# APM32F445 register map
File version: 1.0
CPU: CM4 r0p1, little endian, MPU, FPU, 4 interrupt priority bits
Registers are 32-bit, read-write, reset 0x0 unless marked. A register's access mark holds for its fields unless they carry their own. Offsets are from the block's base; [hi:lo] are bit positions; {n}, {i} and the like mark numbered series.

## PDU0 — Programmable Delay Unit 0
Base 0x40036000
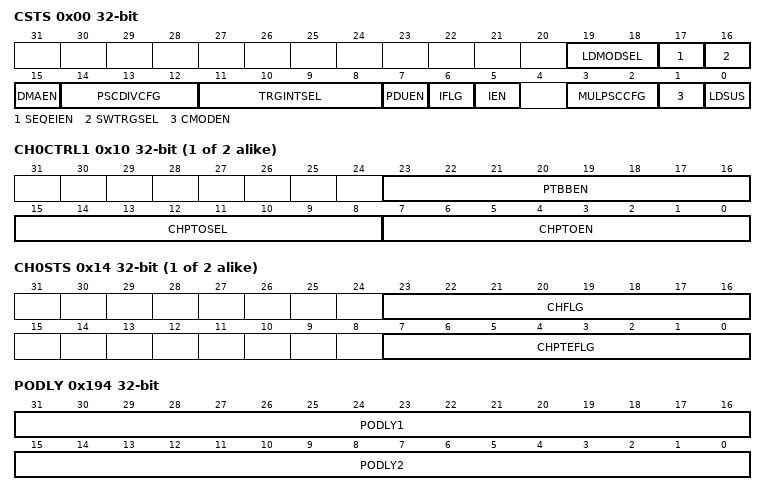
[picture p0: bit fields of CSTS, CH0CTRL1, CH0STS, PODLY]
0x00 CSTS — Control and Status register
  [19:18] LDMODSEL — Load Mode Select
    0=The internal registers are loaded with the values from their buffers, immediately after 1 is written to LDOK; 1=The internal registers are loaded with the values from their buffers when the PDU counter (CNT) = MOD + 1 CNT delay elapsed, after 1 is written to LDOK; 2=The internal registers are loaded with the values from their buffers when a trigger input event is detected, after 1 is written to LDOK; 3=The internal registers are loaded with the values from their buffers when either the PDU counter (CNT) = MOD + 1 CNT delay elapsed, or a trigger input event is detected, after 1 is written to LDOK
  [17] SEQEIEN — Sequence Error Interrupt Enable
    0=PDU sequence error interrupt disabled; 1=PDU sequence error interrupt enabled
  [16] SWTRGSEL wo — Software Trigger Select
  [15] DMAEN — DMA Enable
    0=DMA disabled; 1=DMA enabled
  [14:12] PSCDIVCFG — Prescaler Divider Configure
    0=Counting uses the peripheral clock divided by MULT (the multiplication factor); 1=Counting uses the peripheral clock divided by 2 x MULT (the multiplication factor); 2=Counting uses the peripheral clock divided by 4 x MULT (the multiplication factor); 3=Counting uses the peripheral clock divided by 8 x MULT (the multiplication factor); 4=Counting uses the peripheral clock divided by 16 x MULT (the multiplication factor); 5=Counting uses the peripheral clock divided by 32 x MULT (the multiplication factor); 6=Counting uses the peripheral clock divided by 64 x MULT (the multiplication factor); 7=Counting uses the peripheral clock divided by 128 x MULT (the multiplication factor)
  [11:8] TRGINTSEL — Trigger Input Source Select
    {v}=Trigger-In {v} is selected (v=0..14); 15=Software trigger is selected
  [7] PDUEN — PDU Enable
    0=PDU disabled. Counter is off.; 1=PDU enabled
  [6] IFLG — Interrupt Flag
  [5] IEN — Interrupt Enable
    0=PDU interrupt disabled; 1=PDU interrupt enabled
  [3:2] MULPSCCFG — Multiplication Factor Prescaler Configure
    0=Multiplication factor is 1; 1=Multiplication factor is 10; 2=Multiplication factor is 20; 3=Multiplication factor is 40
  [1] CMODEN — PDU in Continuous Mode Enable
    0=PDU operation in One-Shot mode; 1=PDU operation in Continuous mode
  [0] LDSUS — Load Success
0x04 CNTPRD reset 0xFFFF — Counter Period register
  [15:0] CNTPRD — Counter Period
0x08 CNTCUR ro — Counter Contains Current Value register
  [15:0] CNTCUR — Counter Contains Current Value
0x0C SINTDLY reset 0xFFFF — Scheduling Interrupt Delay Value register
  [15:0] SINTDLY — Scheduling Interrupt Delay Value
{0x10+0x28*i} CH{i}CTRL1 (i=0..1) — Channel n Control register 1
  [23:16] PTBBEN — Pre-Trigger Back-to-Back Operation Enable
    0=PDU channel's corresponding pre-trigger back-to-back operation disabled; 1=PDU channel's corresponding pre-trigger back-to-back operation enabled
  [15:8] CHPTOSEL — Channel Pre-Trigger Output Select
    0=PDU channel's corresponding pre-trigger is in bypassed mode. The pre-trigger asserts one peripheral clock cycle after a rising edge is detected on selected trigger input source or software trigger is selected and SWTRIG is written with 1.; 1=PDU channel's corresponding pre-trigger asserts when the counter reaches the channel delay register and one peripheral clock cycle after a rising edge is detected on selected trigger input source or software trigger is selected and SWTRIG is written with 1
  [7:0] CHPTOEN — Channel Pre-Trigger Output Enable
    0=PDU channel's corresponding pre-trigger disabled; 1=PDU channel's corresponding pre-trigger enabled
{0x14+0x28*i} CH{i}STS (i=0..1) — Channel n Status register
  [23:16] CHFLG — Channel Flags
  [7:0] CHPTEFLG — Channel Pre-trigger Sequence Error Flags
    0=Sequence error not detected on PDU channel's corresponding pre-trigger; 1=Sequence error detected on PDU channel's corresponding pre-trigger. ADCn block can be triggered for a conversion by one pre-trigger from PDU channel n. When one conversion, which is triggered by one of the pre-triggers from PDU channel n, is in progress, new trigger from PDU channel's corresponding pre-trigger m cannot be accepted by ADCn, and ERR[m] is set. Writing 0's to clear the sequence error flags.
{0x18+0x28*i} CH{i}D0 (i=0..1) — Channel n Delay 0 register
  [15:0] CHPTDLY — Channel Pre-trigger Delay Value
{0x1C+0x28*i} CH{i}D1 (i=0..1) — Channel n Delay 1 register
  [15:0] CHPTDLY — Channel Pre-trigger Delay Value
{0x20+0x28*i} CH{i}D2 (i=0..1) — Channel n Delay 2 register
  [15:0] CHPTDLY — Channel Pre-trigger Delay Value
{0x24+0x28*i} CH{i}D3 (i=0..1) — Channel n Delay 3 register
  [15:0] CHPTDLY — Channel Pre-trigger Delay Value
{0x28+0x28*i} CH{i}D4 (i=0..1) — Channel n Delay 4 register
  [15:0] CHPTDLY — Channel Pre-trigger Delay Value
{0x2C+0x28*i} CH{i}D5 (i=0..1) — Channel n Delay 5 register
  [15:0] CHPTDLY — Channel Pre-trigger Delay Value
{0x30+0x28*i} CH{i}D6 (i=0..1) — Channel n Delay 6 register
  [15:0] CHPTDLY — Channel Pre-trigger Delay Value
{0x34+0x28*i} CH{i}D7 (i=0..1) — Channel n Delay 7 register
  [15:0] CHPTDLY — Channel Pre-trigger Delay Value
0x190 POEN — Pulse-Out Enable register
  [7:0] POEN — Pulse Output Enble
    0=PDU Pulse-Out disabled; 1=PDU Pulse-Out enabled
0x194 PODLY — Pulse-Out Delay register
  [31:16] PODLY1 — Pulse Output Delay 1 Value
  [15:0] PODLY2 — Pulse Output Delay 2 Value

## PDU1 — Programmable Delay Unit 1
Base 0x40031000
Registers as PDU0; these are added or differ:
0x190 POEN — Pulse-Out n Enable register
  [7:0] POEN — Pulse Output Enble
    0=PDU Pulse-Out disabled; 1=PDU Pulse-Out enabled
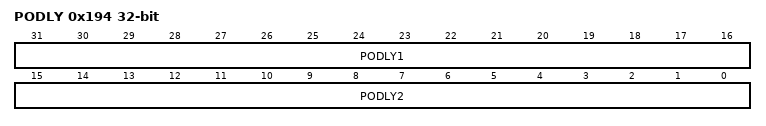
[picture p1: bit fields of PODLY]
0x194 PODLY — Pulse-Out Delay register 0
  [31:16] PODLY1 — Pulse Output Delay 1 Value
  [15:0] PODLY2 — Pulse Output Delay 2 Value
